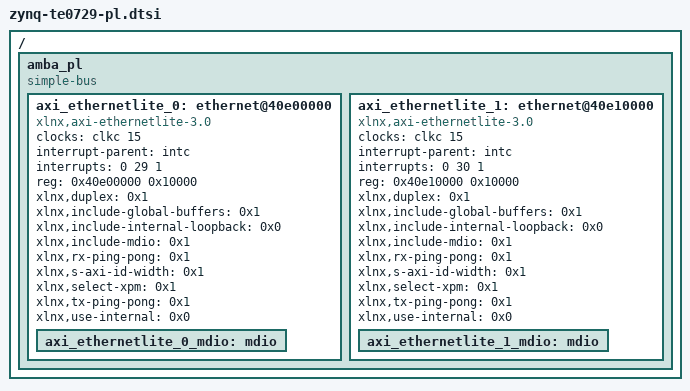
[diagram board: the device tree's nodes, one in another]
/*
 * CAUTION: This file is automatically generated by Xilinx.
 * Version: XSCT
 * Today is: Wed Jun 17 08:33:22 2026
 */


/ {
        amba_pl: amba_pl {
                #address-cells = <1>;
                #size-cells = <1>;
                compatible = "simple-bus";
                ranges ;
                axi_ethernetlite_0: ethernet@40e00000 {
                        clock-names = "s_axi_aclk";
                        clocks = <&clkc 15>;
                        compatible = "xlnx,axi-ethernetlite-3.0", "xlnx,xps-ethernetlite-1.00.a";
                        device_type = "network";
                        interrupt-names = "ip2intc_irpt";
                        interrupt-parent = <&intc>;
                        interrupts = <0 29 1>;
                        reg = <0x40e00000 0x10000>;
                        xlnx,duplex = <0x1>;
                        xlnx,include-global-buffers = <0x1>;
                        xlnx,include-internal-loopback = <0x0>;
                        xlnx,include-mdio = <0x1>;
                        xlnx,rx-ping-pong = <0x1>;
                        xlnx,s-axi-id-width = <0x1>;
                        xlnx,select-xpm = <0x1>;
                        xlnx,tx-ping-pong = <0x1>;
                        xlnx,use-internal = <0x0>;
                        axi_ethernetlite_0_mdio: mdio {
                                #address-cells = <1>;
                                #size-cells = <0>;
                        };
                };
                axi_ethernetlite_1: ethernet@40e10000 {
                        clock-names = "s_axi_aclk";
                        clocks = <&clkc 15>;
                        compatible = "xlnx,axi-ethernetlite-3.0", "xlnx,xps-ethernetlite-1.00.a";
                        device_type = "network";
                        interrupt-names = "ip2intc_irpt";
                        interrupt-parent = <&intc>;
                        interrupts = <0 30 1>;
                        reg = <0x40e10000 0x10000>;
                        xlnx,duplex = <0x1>;
                        xlnx,include-global-buffers = <0x1>;
                        xlnx,include-internal-loopback = <0x0>;
                        xlnx,include-mdio = <0x1>;
                        xlnx,rx-ping-pong = <0x1>;
                        xlnx,s-axi-id-width = <0x1>;
                        xlnx,select-xpm = <0x1>;
                        xlnx,tx-ping-pong = <0x1>;
                        xlnx,use-internal = <0x0>;
                        axi_ethernetlite_1_mdio: mdio {
                                #address-cells = <1>;
                                #size-cells = <0>;
                        };
                };
        };
};
